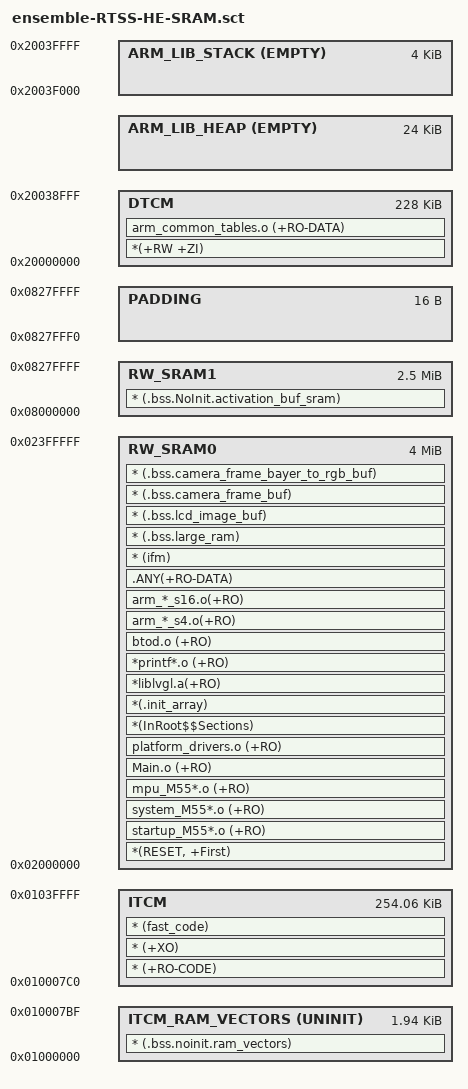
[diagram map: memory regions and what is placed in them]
#! armclang -E --target=arm-arm-none-eabi -mcpu=cortex-m55 -xc
; command above MUST be in first line (no comment above!)

;/* Copyright (C) 2022 Alif Semiconductor - All Rights Reserved.
; * Use, distribution and modification of this code is permitted under the
; * terms stated in the Alif Semiconductor Software License Agreement
; *
; * You should have received a copy of the Alif Semiconductor Software
; * License Agreement with this file. If not, please write to:
; * contact@alifsemi.com, or visit: https://alifsemi.com/license
; *
; */

/*On chip RAM Regions */
#define SRAM0_BASE                0x02000000
#define SRAM0_SIZE                0x00400000		/* 4M */
#define SRAM1_BASE                0x08000000
#define SRAM1_SIZE                0x00280000		/* 2.5M */
#define SRAM6_BASE                0x62000000
#define SRAM6_SIZE                0x00200000		/* 2M */
#define SRAM7_BASE                0x63000000
#define SRAM7_SIZE                0x00080000		/* 512K */
#define SRAM8_BASE                0x63100000
#define SRAM8_SIZE                0x00200000		/* 2M */
#define SRAM9_BASE                0x64000000
#define SRAM9_SIZE                0x000C0000		/* 768K */
/* On Chip NVM */
#define MRAM_BASE                 0x80000000
#define MRAM_SIZE                 0x00580000		/* 5.5M */

/*--------------------- ITCM Configuration ----------------------------------*/
/* SRAM4 is mapped as ITCM */
#define ITCM_BASE                 0x01000000
#define ITCM_SIZE                 0x00040000        /* 256K */

/*--------------------- DTCM Configuration ---------------------------*/
/* SRAM5 is mapped as DTCM */
#define DTCM_BASE                 0x20000000
#define DTCM_SIZE                 0x00040000        /* 256K */

#define __VECTORS_SIZE  (496 * 4)
#define __STACK_SIZE    0x00001000
#define __HEAP_SIZE     0x00006000

;----------------------------------------------------------------------------
;   User Stack & Heap boundary definition
;----------------------------------------------------------------------------
#define __STACK_TOP     (DTCM_BASE + DTCM_SIZE)       /* starts at end of RAM */
#define __HEAP_BASE     (AlignExpr(+0, 8))            /* starts after RW_RAM section, 8 byte aligned */

;----------------------------------------------------------------------------
;  Scatter File Definitions definition
;----------------------------------------------------------------------------
#define __RO_BASE       SRAM0_BASE
#define __RO_SIZE       SRAM0_SIZE

#define __RW_BASE       DTCM_BASE
#define __RW_SIZE      (DTCM_SIZE - __STACK_SIZE - __HEAP_SIZE)


LR_SRAM0 __RO_BASE __RO_SIZE  {                       ; load region size_region
  RW_SRAM0 __RO_BASE __RO_SIZE {                      ; load address = execution address
   ; SRAM has start-up code, LVGL read-only, and most constant data
   *(RESET, +First)
   startup_M55*.o (+RO)
   system_M55*.o (+RO)
   mpu_M55*.o (+RO)
   Main.o (+RO)
   platform_drivers.o (+RO)
   *(InRoot$$Sections)
   *(.init_array)
   *liblvgl.a(+RO)
   *printf*.o (+RO)
   btod.o (+RO)
   arm_*_s4.o(+RO)
   arm_*_s16.o(+RO)
   .ANY(+RO-DATA)

      * (ifm)                                ; Baked-in inputs
      * (.bss.large_ram)                     ; Large LVGL buffers
      * (.bss.lcd_image_buf)
      * (.bss.camera_frame_buf)              ; Camera Frame Buffer
      * (.bss.camera_frame_bayer_to_rgb_buf) ; (Optional) Camera Frame Buffer for Bayer to RGB Convertion.
  }

  RW_SRAM1 SRAM1_BASE SRAM1_SIZE  {  ; 2.5MB ----------------------------

      ; activation buffers a.k.a tensor arena when memory mode dedicated sram
      * (.bss.NoInit.activation_buf_sram)
  }

  ITCM_RAM_VECTORS ITCM_BASE UNINIT ALIGN 2048 __VECTORS_SIZE {
      * (.bss.noinit.ram_vectors)
  }

  ITCM ITCM_BASE+__VECTORS_SIZE ITCM_SIZE-__VECTORS_SIZE {  ; --------------------------------
      ; ITCM has non-startup code, except for non-fast LVGL, and RAM vectors
      * (+RO-CODE)
      * (+XO)
      * (fast_code)
  }

  ;-----------------------------------------------------
  ; R/W region - remaining part of the DTCM region
  ; Other parts of this region used up by stack + heap.
  ;-----------------------------------------------------
  DTCM __RW_BASE __RW_SIZE  {  ; RW data in DTCM
      ; DTCM has CMSIS-DSP tables and all read-write data, except image and NPU buffers
      *(+RW +ZI)
      arm_common_tables.o (+RO-DATA)
  }

  ARM_LIB_HEAP  __HEAP_BASE EMPTY  __HEAP_SIZE  {  }
  ARM_LIB_STACK __STACK_TOP EMPTY -__STACK_SIZE {  }

  PADDING SRAM1_BASE+SRAM1_SIZE-16 ALIGN 16 FILL 0 16  {  }
}
